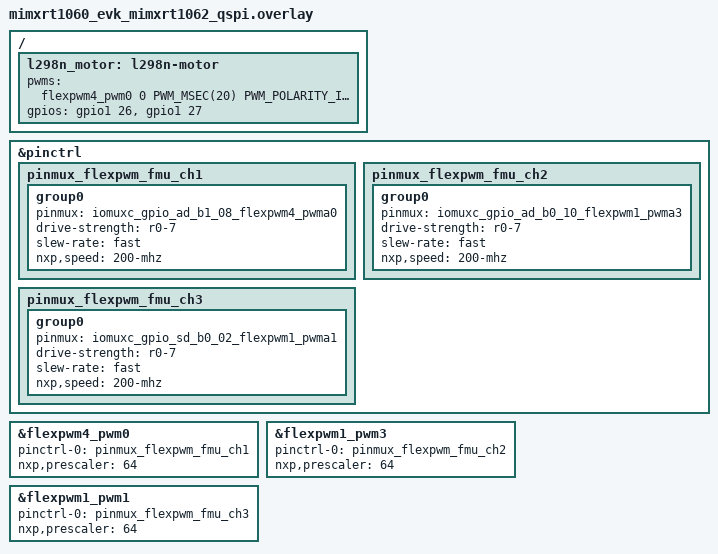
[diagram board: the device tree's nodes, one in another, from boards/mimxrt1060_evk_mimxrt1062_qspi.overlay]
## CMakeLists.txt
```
# SPDX-License-Identifier: Apache-2.0

cmake_minimum_required(VERSION 3.20.0)

find_package(Zephyr REQUIRED HINTS $ENV{ZEPHYR_BASE})
project(mordor)

FILE(GLOB app_sources src/*.c)
FILE(GLOB foc_sources src/foc/*.c)

set(FOC_INC ${APPLICATION_SOURCE_DIR}/include/foc)

target_sources(app PRIVATE ${app_sources} ${foc_sources})

target_include_directories(app PRIVATE  ${FOC_INC})

# Optionally, include the tests directory if testing
if(CONFIG_TESTING)
    add_subdirectory(tests)
endif()
```

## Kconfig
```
config STEPPER_FOC
       bool "Enable stepper FOC"
       default n

source "Kconfig.zephyr"
```

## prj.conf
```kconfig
CONFIG_LOG=y

CONFIG_CAN=y
CONFIG_GPIO=y
CONFIG_CAN_ACCEPT_RTR=y

CONFIG_NETWORKING=y
```

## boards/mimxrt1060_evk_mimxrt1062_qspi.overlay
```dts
/ {
        l298n_motor: l298n-motor{
                pwms = <&flexpwm4_pwm0 0 PWM_MSEC(20) PWM_POLARITY_INVERTED>;
                // Pins order: IN3,IN4
                gpios = <&gpio1 26 GPIO_ACTIVE_HIGH>, <&gpio1 27 GPIO_ACTIVE_HIGH>;
        };
};

&pinctrl{
	pinmux_flexpwm_fmu_ch1: pinmux_flexpwm_fmu_ch1 {
		group0 {
			pinmux = <&iomuxc_gpio_ad_b1_08_flexpwm4_pwma0>;

			drive-strength = "r0-7";
			slew-rate = "fast";
			nxp,speed = "200-mhz";
		};
	};

	pinmux_flexpwm_fmu_ch2: pinmux_flexpwm_fmu_ch2 {
		group0 {
			pinmux = <&iomuxc_gpio_ad_b0_10_flexpwm1_pwma3>;

			drive-strength = "r0-7";
			slew-rate = "fast";
			nxp,speed = "200-mhz";
		};
	};

	pinmux_flexpwm_fmu_ch3: pinmux_flexpwm_fmu_ch3 {
		group0 {
			pinmux = <&iomuxc_gpio_sd_b0_02_flexpwm1_pwma1>;

			drive-strength = "r0-7";
			slew-rate = "fast";
			nxp,speed = "200-mhz";
		};
	};

};

&flexpwm4_pwm0 {
  status = "okay";
  pinctrl-0 = <&pinmux_flexpwm_fmu_ch1>;
  pinctrl-names = "default";
  nxp,prescaler = <64>;
};

&flexpwm1_pwm3 {
  status = "okay";
  pinctrl-0 = <&pinmux_flexpwm_fmu_ch2>;
  pinctrl-names = "default";
  nxp,prescaler = <64>;
};

&flexpwm1_pwm1 {
  status = "okay";
  pinctrl-0 = <&pinmux_flexpwm_fmu_ch3>;
  pinctrl-names = "default";
  nxp,prescaler = <64>;
};
```

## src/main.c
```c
#include <zephyr/logging/log.h>
LOG_MODULE_REGISTER(mordor);

#include <zephyr/kernel.h>
#include <zephyr/net/net_if.h>
#include <zephyr/sys/reboot.h>

#include "canbus.h"
#include "common.h"
#include "ethernet.h"
#include "foc_speed.h"

int main(void) {
  struct net_if iface;
  LOG_INF("Initializing CAN");
  if (!init_canbus()) {
    LOG_WRN("Failed to initialize canbus");
  }

  LOG_INF("Initializing ethernet");
  if (!init_ethernet(&iface)) {
    LOG_WRN("Failed to initialize ethernet");
  }

  foc_speed_t foc = {0};
  foc_speed_init(&foc);

  while (1) {
    foc_speed_step(&foc);

    k_sleep(K_USEC(20));
  }

  return 0;
}
```

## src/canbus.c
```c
#include "canbus.h"
#include "common.h"

#include <zephyr/logging/log.h>
LOG_MODULE_DECLARE(mordor, LOG_LEVEL_INF);

#include <zephyr/kernel.h>

// using uniform values for both threads, at least for now
#define THREAD_STACK_SIZE 512
#define THREAD_PRIORITY 2

CAN_MSGQ_DEFINE(canbus_rx_msgq, 8);

K_TIMER_DEFINE(can_tx_timer, NULL, NULL);

K_THREAD_STACK_DEFINE(rx_thread_stack, THREAD_STACK_SIZE);
K_THREAD_STACK_DEFINE(tx_thread_stack, THREAD_STACK_SIZE);

struct k_thread rx_thread_data;
struct k_thread tx_thread_data;

struct k_mutex candata_mutex;

const struct device *const can_device = DEVICE_DT_GET(CANBUS_NODE);

void can_tx_thread(void *arg1, void *arg2, void *arg3) {
  // assuming
  ARG_UNUSED(arg1);
  ARG_UNUSED(arg2);
  ARG_UNUSED(arg3);

  int ret;
  struct can_frame frame = {0};

  k_timer_start(&can_tx_timer, K_SECONDS(1), K_SECONDS(1));

  while (1) {
    k_timer_status_sync(&can_tx_timer);

    // fill in frame data using args

    // sender blocks until message is sent
    ret = can_send(can_device, &frame, K_FOREVER, NULL, NULL);
    if (ret != 0) {
      LOG_INF("CAN send has failed [%d]", ret);
    }
  }
}

void can_rx_thread(void *arg1, void *arg2, void *arg3) {
  ARG_UNUSED(arg1);
  ARG_UNUSED(arg2);
  ARG_UNUSED(arg3);

  struct can_frame frame;
  // set can filter (mask = 0, takes all frames std and ext)
  // lets peek
  const struct can_filter filter = {
      .flags = CAN_FILTER_IDE, .id = 0, .mask = 0};

  can_add_rx_filter_msgq(can_device, &canbus_rx_msgq, &filter);

  while (1) {
    k_msgq_get(&canbus_rx_msgq, &frame, K_FOREVER);

    k_mutex_lock(&candata_mutex, K_FOREVER);

    // process our frames

    k_mutex_unlock(&candata_mutex);
  }
}

int init_canbus(void) {

  int ret;
  k_tid_t rx_tid, tx_tid;

  if (!device_is_ready(can_device)) {
    LOG_ERR("CAN device %s not ready\n", can_device->name);
    return APP_FAIL;
  }

  ret = can_start(can_device);
  if (ret != 0) {
    LOG_ERR("CAN could not start controller [%d]", ret);
    return APP_FAIL;
  }

  LOG_INF("Starting tx thread...\n");
  tx_tid = k_thread_create(
      &tx_thread_data, tx_thread_stack, K_THREAD_STACK_SIZEOF(tx_thread_stack),
      can_tx_thread, NULL, NULL, NULL, THREAD_PRIORITY, 0, K_NO_WAIT);
  if (!tx_tid) {
    LOG_INF("ERROR spawning tx thread\n");
  }

  LOG_INF("Starting rx thread...\n");
  rx_tid = k_thread_create(
      &rx_thread_data, rx_thread_stack, K_THREAD_STACK_SIZEOF(rx_thread_stack),
      can_rx_thread, NULL, NULL, NULL, THREAD_PRIORITY, 0, K_NO_WAIT);
  if (!rx_tid) {
    LOG_INF("ERROR spawning rx thread\n");
  }

  return APP_SUCC;
}
```

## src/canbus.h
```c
#ifndef __CANBUS_H__
#define __CANBUS_H__

#include <zephyr/drivers/can.h>

#define CANBUS_NODE DT_CHOSEN(zephyr_canbus)

int init_canbus(void);

#endif
```

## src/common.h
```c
#ifndef __COMMON_H__
#define __COMMON_H__

#define APP_SUCC 0
#define APP_FAIL 1

#endif
```

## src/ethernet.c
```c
#include <zephyr/logging/log.h>
LOG_MODULE_DECLARE(mordor, LOG_LEVEL_INF);

#include <errno.h>
#include <zephyr/kernel.h>

#include <zephyr/net/ethernet.h>
#include <zephyr/net/net_core.h>
#include <zephyr/net/net_if.h>
#include <zephyr/net/net_l2.h>

static int setup_iface(struct net_if *iface, const char *ipv4_addr) {
  struct net_if_addr *ifaddr;
  struct in_addr addr4;

  if (net_addr_pton(AF_INET, ipv4_addr, &addr4)) {
    LOG_ERR("Invalid address: %s", ipv4_addr);
    return -EINVAL;
  }

  ifaddr = net_if_ipv4_addr_add(iface, &addr4, NET_ADDR_MANUAL, 0);
  if (!ifaddr) {
    LOG_ERR("Cannot add %s to interface %p", ipv4_addr, iface);
    return -EINVAL;
  }

  return 0;
}

static enum net_verdict parse_lldp(struct net_if *iface, struct net_pkt *pkt) {
  LOG_DBG("iface %p Parsing LLDP, len %zu", iface, net_pkt_get_len(pkt));

  net_pkt_cursor_init(pkt);

  while (1) {
    uint16_t type_length;
    uint16_t length;
    uint8_t type;

    if (net_pkt_read_be16(pkt, &type_length)) {
      LOG_DBG("End LLDP DU TLV");
      break;
    }

    length = type_length & 0x1FF;
    type = (uint8_t)(type_length >> 9);

    /* Skip for now data */
    if (net_pkt_skip(pkt, length)) {
      LOG_DBG("");
      break;
    }

    switch (type) {
    case LLDP_TLV_CHASSIS_ID:
      LOG_DBG("Chassis ID");
      break;
    case LLDP_TLV_PORT_ID:
      LOG_DBG("Port ID");
      break;
    case LLDP_TLV_TTL:
      LOG_DBG("TTL");
      break;
    default:
      LOG_DBG("TLV Not parsed");
      break;
    }

    LOG_DBG("type_length %u type %u length %u", type_length, type, length);
  }

  /* Let stack to free the packet */
  return NET_DROP;
}

int init_ethernet(struct net_if *iface) {
  enum ethernet_hw_caps caps;

  iface = net_if_get_first_by_type(&NET_L2_GET_NAME(ETHERNET));
  if (!iface) {
    LOG_ERR("No ethernet interfaces found.");
    return -ENOENT;
  }

  caps = net_eth_get_hw_capabilities(iface);
  if (!(caps & ETHERNET_LLDP)) {
    LOG_ERR("Interface %p does not support %s", iface, "LLDP");
    LOG_ERR("Cannot continue!");
    return -ENOENT;
  }

  setup_iface(iface, "0.0.0.0");

  net_lldp_register_callback(iface, parse_lldp);

  return 0;
}
```

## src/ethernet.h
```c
#ifndef __ETHERNET_H__
#define __ETHERNET_H__

#include <zephyr/net/net_if.h>

int init_ethernet(struct net_if *iface);
int stop_ethernet(void);

#endif
```
